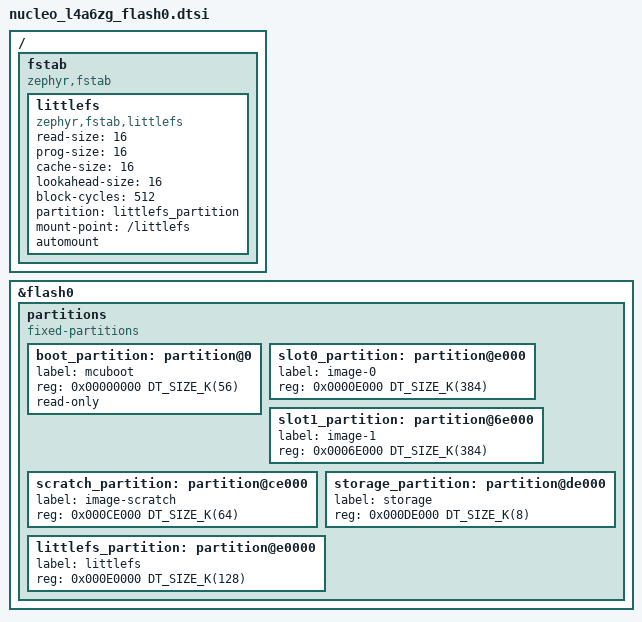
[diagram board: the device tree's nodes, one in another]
/**
 * @file      nucleo_l4a6zg_flash0.dtsi
 * @brief     Nucleo STM32L4A6 flash0 overlay include
 *
 * Copyright joelguittet and mender-mcu-client contributors
 *
 * Licensed under the Apache License, Version 2.0 (the "License");
 * you may not use this file except in compliance with the License.
 * You may obtain a copy of the License at
 *
 *     http://www.apache.org/licenses/LICENSE-2.0
 *
 * Unless required by applicable law or agreed to in writing, software
 * distributed under the License is distributed on an "AS IS" BASIS,
 * WITHOUT WARRANTIES OR CONDITIONS OF ANY KIND, either express or implied.
 * See the License for the specific language governing permissions and
 * limitations under the License.
 */

/ {
    fstab {
        compatible = "zephyr,fstab";
        littlefs: littlefs {
            compatible = "zephyr,fstab,littlefs";
            read-size = <16>;
            prog-size = <16>;
            cache-size = <16>;
            lookahead-size = <16>;
            block-cycles = <512>;
            partition = <&littlefs_partition>;
            mount-point = "/littlefs";
            automount;
        };
    };
};

&flash0 {
    partitions {
        compatible = "fixed-partitions";
        #address-cells = <1>;
        #size-cells = <1>;
        /* Bootloader slot: 56KB */
        boot_partition: partition@0 {
            label = "mcuboot";
            reg = <0x00000000 DT_SIZE_K(56)>;
            read-only;
        };
        /* Application slot: 384KB */
        slot0_partition: partition@e000 {
            label = "image-0";
            reg = <0x0000E000 DT_SIZE_K(384)>;
        };
        /* Update slot: 384KB */
        slot1_partition: partition@6e000 {
            label = "image-1";
            reg = <0x0006E000 DT_SIZE_K(384)>;
        };
        /* Swap slot: 64KB */
        scratch_partition: partition@ce000 {
            label = "image-scratch";
            reg = <0x000CE000 DT_SIZE_K(64)>;
        };
        /* Storage slot: 8KB */
        storage_partition: partition@de000 {
            label = "storage";
            reg = <0x000DE000 DT_SIZE_K(8)>;
        };
        /* LittleFS slot: 128KB */
        littlefs_partition: partition@e0000 {
            label = "littlefs";
            reg = <0x000E0000 DT_SIZE_K(128)>;
        };
    };
};
